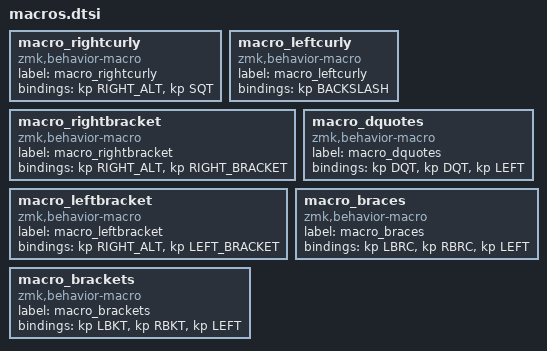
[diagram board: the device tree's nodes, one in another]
macro_rightcurly: macro_rightcurly{
compatible = "zmk,behavior-macro";
label = "macro_rightcurly";
#binding-cells = <0>;
bindings = <&kp RIGHT_ALT>, <&kp SQT>;
};
macro_leftcurly: macro_leftcurly{
compatible = "zmk,behavior-macro";
label = "macro_leftcurly";
#binding-cells = <0>;
bindings = <&kp BACKSLASH>;
};
macro_rightbracket: macro_rightbracket{
compatible = "zmk,behavior-macro";
label = "macro_rightbracket";
#binding-cells = <0>;
bindings = <&kp RIGHT_ALT>, <&kp RIGHT_BRACKET>;
};
macro_leftbracket: macro_leftbracket{
compatible = "zmk,behavior-macro";
label = "macro_leftbracket";
#binding-cells = <0>;
bindings = <&kp RIGHT_ALT>, <&kp LEFT_BRACKET>;
};
macro_dquotes: macro_dquotes{
compatible = "zmk,behavior-macro";
label = "macro_dquotes";
#binding-cells = <0>;
bindings = <&kp DQT>, <&kp DQT>, <&kp LEFT>;
};
macro_braces: macro_braces{
compatible = "zmk,behavior-macro";
label = "macro_braces";
#binding-cells = <0>;
bindings = <&kp LBRC>, <&kp RBRC>, <&kp LEFT>;
};
macro_brackets: macro_brackets{
compatible = "zmk,behavior-macro";
label = "macro_brackets";
#binding-cells = <0>;
bindings = <&kp LBKT>, <&kp RBKT>, <&kp LEFT>;
};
